# STM32U5A9 register map
File version: 1.0
CPU: CM33 r0p1, little endian, MPU, FPU, 4 interrupt priority bits
Registers are 32-bit, read-write, reset 0x0 unless marked. A register's access mark holds for its fields unless they carry their own. Offsets are from the block's base; [hi:lo] are bit positions; lines under a group give offsets from that group; {n}, {i} and the like mark numbered series.

## DLYBOS1 — The delay block (DLYB) is used to generate an output clock that is dephased from the input clock
Base 0x420CF000
Same registers: DLYBSD1 0x420C8400, DLYBSD2 0x420C8800, DLYBOS2 0x420CF400, SEC_DLYBSD1 0x520C8400, SEC_DLYBSD2 0x520C8800, SEC_DLYBOS1 0x520CF000, SEC_DLYBOS2 0x520CF400
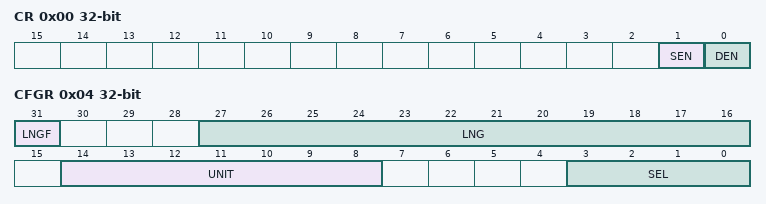
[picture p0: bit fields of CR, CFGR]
0x00 CR — control register
  [1] SEN — OPALPM
  [0] DEN — Operational amplifier Enable
0x04 CFGR access per field — configuration register
  [31] LNGF ro, [27:16] LNG ro, [14:8] UNIT rw, [3:0] SEL rw

## FMAC — Filter Math Accelerator
Base 0x40021400
Same registers: SEC_FMAC 0x50021400
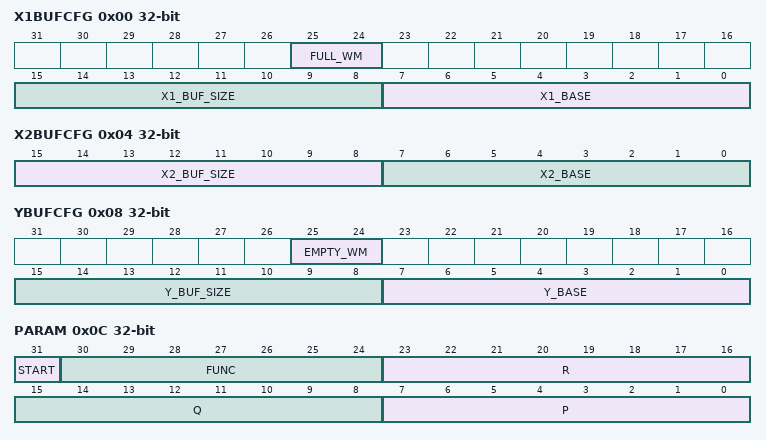
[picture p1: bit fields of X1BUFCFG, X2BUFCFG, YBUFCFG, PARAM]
0x00 X1BUFCFG — FMAC X1 Buffer Configuration register
  [25:24] FULL_WM — Watermark for buffer full flag
  [15:8] X1_BUF_SIZE — Allocated size of X1 buffer in 16-bit words
  [7:0] X1_BASE — Base address of X1 buffer
0x04 X2BUFCFG — FMAC X2 Buffer Configuration register
  [15:8] X2_BUF_SIZE — Size of X2 buffer in 16-bit words
  [7:0] X2_BASE — Base address of X2 buffer
0x08 YBUFCFG — FMAC Y Buffer Configuration register
  [25:24] EMPTY_WM — Watermark for buffer empty flag
  [15:8] Y_BUF_SIZE — Size of Y buffer in 16-bit words
  [7:0] Y_BASE — Base address of Y buffer
0x0C PARAM — FMAC Parameter register
  [31] START — Enable execution
  [30:24] FUNC — Function
  [23:16] R — Input parameter R
  [15:8] Q — Input parameter Q
  [7:0] P — Input parameter P
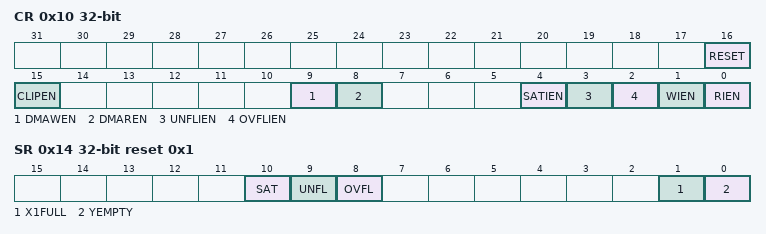
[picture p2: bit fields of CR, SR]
0x10 CR — FMAC Control register
  [16] RESET — Reset FMAC unit
  [15] CLIPEN — Enable clipping
  [9] DMAWEN — Enable DMA write channel requests
  [8] DMAREN — Enable DMA read channel requests
  [4] SATIEN — Enable saturation error interrupts
  [3] UNFLIEN — Enable underflow error interrupts
  [2] OVFLIEN — Enable overflow error interrupts
  [1] WIEN — Enable write interrupt
  [0] RIEN — Enable read interrupt
0x14 SR ro reset 0x1 — FMAC Status register
  [10] SAT — Saturation error flag
  [9] UNFL — Underflow error flag
  [8] OVFL — Overflow error flag
  [1] X1FULL — X1 buffer full flag
  [0] YEMPTY — Y buffer empty flag
0x18 WDATA wo — FMAC Write Data register
  [15:0] WDATA — Write data
0x1C RDATA ro — FMAC Read Data register
  [15:0] RDATA — Read data

## GFXMMU
Base 0x4002C000
Same registers: SEC_GFXMMU 0x5002C000
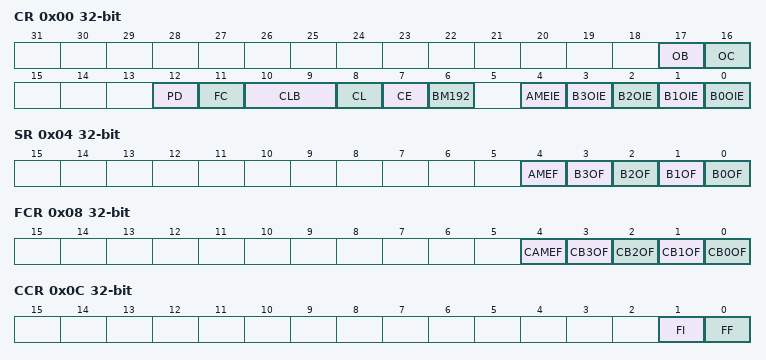
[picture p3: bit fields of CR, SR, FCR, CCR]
0x00 CR — GFXMMU configuration register
  [17] OB — Outter bufferability This bit configure the bufferability of an access generated by the GFXMMU cache.
  [16] OC — Outter cachability This bit configure the cachability of an access generated by the GFXMMU cache.
  [12] PD — Prefetch disable This bit disables the prefetch of the cache.
  [11] FC — Force caching This bit force the caching into the cache regardless of the MPU attributes. The cache must be enable (CE bit set).
  [10:9] CLB — Cache lock buffer This field select the buffer on which the cache is locked.
  [8] CL — Cache lock This bit lock the cache onto the buffer defined in the CLB field.
  [7] CE — Cache enable This bit enables the cache unit.
  [6] BM192 — 192 Block mode This bit defines the number of blocks per line
  [4] AMEIE — AHB master error interrupt enable This bit enables the AHB master error interrupt.
  [n] B{n}OIE (n=0..3) — Buffer {n} overflow interrupt enable This bit enables the buffer {n} overflow interrupt.
0x04 SR ro — GFXMMU status register
  [4] AMEF — AHB master error flag This bit is set when an AHB error happens during a transaction. It is cleared by writing 1 to CAMEF.
  [n] B{n}OF (n=0..3) — Buffer {n} overflow flag This bit is set when an overflow occurs during the offset calculation of the buffer {n}. It is cleared by writing 1 to CB{n}OF.
0x08 FCR — GFXMMU flag clear register
  [4] CAMEF — Clear AHB master error flag Writing 1 clears the AHB master error flag in the GFXMMU_SR register.
  [n] CB{n}OF (n=0..3) — Clear buffer {n} overflow flag Writing 1 clears the buffer {n} overflow flag in the GFXMMU_SR register.
0x0C CCR — GFXMMU cache control register
  [1] FI — Force invalidate When set, the cache entries are invalidated. This bit is reset by hardware when the invalidation is complete. Write 0 has no effect.
  [0] FF — Force flush When set, the cache entries are flushed. This bit is reset by hardware when the flushing is complete. Write 0 has no effect.
0x10 DVR — GFXMMU default value register
  [31:0] DV — Default value This field indicates the default 32-bit value which is returned when a master accesses a virtual memory location not physically mapped.
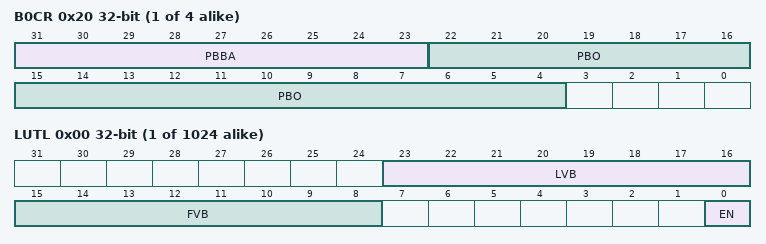
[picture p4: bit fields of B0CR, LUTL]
{0x20+4i} B{i}CR (i=0..3) — GFXMMU buffer {i} configuration register
  [31:23] PBBA — Physical buffer base address Base address MSB of the physical buffer.
  [22:4] PBO — Physical buffer offset Offset of the physical buffer.
{0x1000+8i} LUT{i} (i=0..1023) group — Cluster LUT{i}, containing LUT*L, LUT*H
  0x00 LUTL — Graphic MMU LUT entry x low
    [23:16] LVB — Last Valid Block Number of the last valid block of line number X.
    [15:8] FVB — First Valid Block Number of the first valid block of line number x.
    [0] EN — Enable Line enable.
  0x04 LUTH — Graphic MMU LUT entry x high
    [21:4] LO — Line offset Line offset of line number x (i.e. offset of block 0 of line x)
